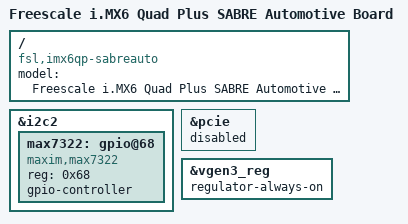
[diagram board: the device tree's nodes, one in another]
// SPDX-License-Identifier: GPL-2.0+ OR MIT
//
// Copyright 2016 Freescale Semiconductor, Inc.

/dts-v1/;

#include "imx6qp.dtsi"
#include "imx6qdl-sabreauto.dtsi"

/ {
	model = "Freescale i.MX6 Quad Plus SABRE Automotive Board";
	compatible = "fsl,imx6qp-sabreauto", "fsl,imx6qp";
};

&i2c2 {
	max7322: gpio@68 {
		compatible = "maxim,max7322";
		reg = <0x68>;
		gpio-controller;
		#gpio-cells = <2>;
	};
};

&pcie {
	status = "disabled";
};

&vgen3_reg {
	regulator-always-on;
};
